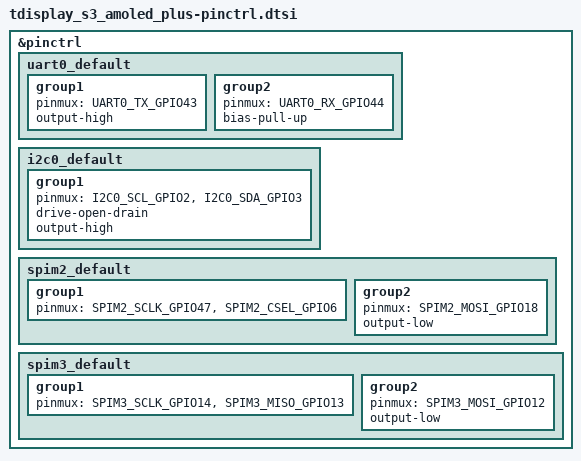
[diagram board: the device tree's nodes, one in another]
/*
 * SPDX-FileCopyrightText: Copyright The Zephyr Project Contributors
 * SPDX-License-Identifier: Apache-2.0
 */

#include <zephyr/dt-bindings/pinctrl/esp32s3-pinctrl.h>

&pinctrl {
	uart0_default: uart0_default {
		group1 {
			pinmux = <UART0_TX_GPIO43>;
			output-high;
		};

		group2 {
			pinmux = <UART0_RX_GPIO44>;
			bias-pull-up;
		};
	};

	i2c0_default: i2c0_default {
		group1 {
			pinmux = <I2C0_SCL_GPIO2>, <I2C0_SDA_GPIO3>;
			drive-open-drain;
			output-high;
		};
	};

	spim2_default: spim2_default {
		group1 {
			pinmux = <SPIM2_SCLK_GPIO47>, <SPIM2_CSEL_GPIO6>;
		};

		group2 {
			pinmux = <SPIM2_MOSI_GPIO18>;
			output-low;
		};
	};

	spim3_default: spim3_default {
		group1 {
			pinmux = <SPIM3_SCLK_GPIO14>, <SPIM3_MISO_GPIO13>;
		};

		group2 {
			pinmux = <SPIM3_MOSI_GPIO12>;
			output-low;
		};
	};
};
